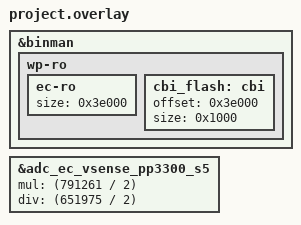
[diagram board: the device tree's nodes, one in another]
/* Copyright 2024 The ChromiumOS Authors
 * Use of this source code is governed by a BSD-style license that can be
 * found in the LICENSE file.
 */

#include <cros/cbi_flash.dtsi>

/* Trulo program common DTS includes */
#include "../cbi.dtsi"
#include "../generated.dtsi"
#include "../i2c.dtsi"
#include "../ite_hibernate.dtsi"
#include "../power_signals.dtsi"
#include "../trulo.dtsi"

/* Trulo project DTS includes*/
#include "battery.dtsi"
#include "cbi.dtsi"
#include "gpio.dtsi"
#include "i2c.dtsi"
#include "keyboard.dtsi"
#include "led_pins.dtsi"
#include "led_policy.dtsi"
#include "temp_sensors.dtsi"
#include "usb_typec.dtsi"
#include "usba.dtsi"


/* Trulo overrides follow... */

&binman {
	wp-ro {
		ec-ro {
			size = <0x3e000>;
		};
		cbi_flash: cbi {
			/*
			 * CBI section size is 0x1000 bytes, the
			 * CBI portion lies at the end of EC_RO section.
			 */
			offset = <0x3e000>;
			size = <0x1000>;
		};
	};
};

&adc_ec_vsense_pp3300_s5 {
	/*
	 * Voltage divider on input has 47k upper and 220k lower legs with
	 * 2714 mV full-scale reading on the ADC. Apply the largest possible
	 * multiplier (without overflowing int32) to get the best possible
	 * approximation of the actual ratio, but derate by a factor of two to
	 * ensure unexpectedly high values won't overflow.
	 */
	mul = <(791261 / 2)>;
	div = <(651975 / 2)>;
};
